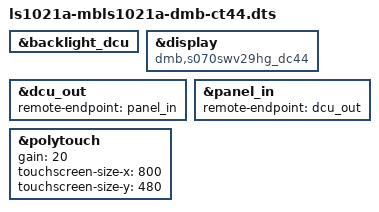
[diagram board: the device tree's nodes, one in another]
// SPDX-License-Identifier: (GPL-2.0-or-later OR X11)
/*
 * Copyright 2013-2014 Freescale Semiconductor, Inc.
 * Copyright 2018-2020 TQ-Systems GmbH
 */

/dts-v1/;
#include "ls1021a-mbls1021a.dtsi"

&backlight_dcu {
	status = "okay";
};

&display {
	compatible = "dmb,s070swv29hg_dc44";
};

&dcu_out {
	remote-endpoint = <&panel_in>;
};

&panel_in {
	remote-endpoint = <&dcu_out>;
};

&polytouch {
	gain = <20>;
	touchscreen-size-x = <800>;
	touchscreen-size-y = <480>;
	status = "okay";
};
